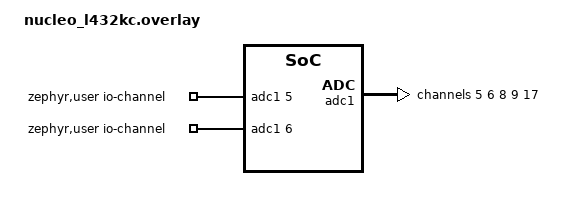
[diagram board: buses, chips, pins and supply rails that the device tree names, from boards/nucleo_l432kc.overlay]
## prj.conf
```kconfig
CONFIG_ADC=y
CONFIG_ADC_STM32=y
CONFIG_SENSOR=y
CONFIG_CBPRINTF_FP_SUPPORT=y
CONFIG_NEWLIB_LIBC=y
CONFIG_NEWLIB_LIBC_FLOAT_PRINTF=y
```

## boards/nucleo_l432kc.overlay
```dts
/ {
	zephyr,user {
		/* adjust channel number according to pinmux in board.dts */
		io-channels = <&adc1 5>, <&adc1 6>;
	};

	die_temp: dietemp {
		status = "okay";
	};
};

&adc1 {
    status = "okay";
	#address-cells = <1>;
	#size-cells = <0>;
	st,adc-clock-source = "SYNC";
	st,adc-prescaler = <4>;
    st,adc-oversampler = "OVERSAMPLER_EXTENDED";

	channel@5 {
		reg = <0x05>;
		zephyr,gain = "ADC_GAIN_1";
		zephyr,reference = "ADC_REF_INTERNAL";
		zephyr,acquisition-time = <ADC_ACQ_TIME_DEFAULT>;
		zephyr,resolution = <12>;
        zephyr,oversampling = <4>;
	};
    channel@6 {
		reg = <0x06>;
		zephyr,gain = "ADC_GAIN_1";
		zephyr,reference = "ADC_REF_INTERNAL";
		zephyr,acquisition-time = <ADC_ACQ_TIME_DEFAULT>;
		zephyr,resolution = <12>;
        zephyr,oversampling = <4>;
	};
    channel@8 {
		reg = <0x08>;
		zephyr,gain = "ADC_GAIN_1";
		zephyr,reference = "ADC_REF_INTERNAL";
		zephyr,acquisition-time = <ADC_ACQ_TIME_DEFAULT>;
		zephyr,resolution = <12>;
        //zephyr,oversampling = <4>;
	};
    channel@9 {
		reg = <0x09>;
		zephyr,gain = "ADC_GAIN_1";
		zephyr,reference = "ADC_REF_INTERNAL";
		zephyr,acquisition-time = <ADC_ACQ_TIME_DEFAULT>;
		zephyr,resolution = <12>;
        //zephyr,oversampling = <4>;
	};
	channel@17 {
		reg = <0x11>;
		zephyr,gain = "ADC_GAIN_1";
		zephyr,reference = "ADC_REF_INTERNAL";
		zephyr,acquisition-time = <ADC_ACQ_TIME_DEFAULT>;
		zephyr,resolution = <12>;
	};
};
```

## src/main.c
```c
#include <zephyr/device.h>
#include <zephyr/devicetree.h>
#include <zephyr/kernel.h>
#include <zephyr/sys/printk.h>
#include <zephyr/drivers/sensor.h>

static const struct device *const tempSensor = DEVICE_DT_GET(DT_NODELABEL(die_temp));

int main(void)
{
	struct sensor_value temp;
	int ret;

	if (!device_is_ready(tempSensor)) {
		printk("sensor: device not ready.\n");
		return 0;
	}

	while (1) {
		ret = sensor_sample_fetch(tempSensor);
		if (ret) {
			printk("sensor_sample_fetch failed ret %d\n", ret);
			return 0;
		}

		ret = sensor_channel_get(tempSensor, SENSOR_CHAN_DIE_TEMP, &temp);

		printk("Temperature: %f\n", sensor_value_to_double(&temp));

		k_sleep(K_MSEC(500));
	}
	return 0;
}
```
